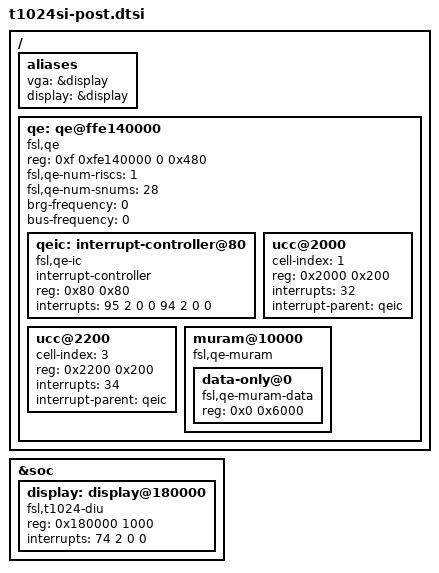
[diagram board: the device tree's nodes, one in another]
#include "t1023si-post.dtsi"
/ {
	aliases {
		vga = &display;
		display = &display;
	};
	qe:qe@ffe140000 {
		#address-cells = <1>;
		#size-cells = <1>;
		device_type = "qe";
		compatible = "fsl,qe";
		ranges = <0x0 0xf 0xfe140000 0x40000>;
		reg = <0xf 0xfe140000 0 0x480>;
		fsl,qe-num-riscs = <1>;
		fsl,qe-num-snums = <28>;
		brg-frequency = <0>;
		bus-frequency = <0>;
	};
};
&soc {
	display:display@180000 {
		compatible = "fsl,t1024-diu", "fsl,diu";
		reg = <0x180000 1000>;
		interrupts = <74 2 0 0>;
	};
};
&qe {
	qeic: interrupt-controller@80 {
		interrupt-controller;
		compatible = "fsl,qe-ic";
		#address-cells = <0>;
		#interrupt-cells = <1>;
		reg = <0x80 0x80>;
		interrupts = <95 2 0 0  94 2 0 0>;  
	};
	ucc@2000 {
		cell-index = <1>;
		reg = <0x2000 0x200>;
		interrupts = <32>;
		interrupt-parent = <&qeic>;
	};
	ucc@2200 {
		cell-index = <3>;
		reg = <0x2200 0x200>;
		interrupts = <34>;
		interrupt-parent = <&qeic>;
	};
	muram@10000 {
		#address-cells = <1>;
		#size-cells = <1>;
		compatible = "fsl,qe-muram", "fsl,cpm-muram";
		ranges = <0x0 0x10000 0x6000>;
		data-only@0 {
			compatible = "fsl,qe-muram-data", "fsl,cpm-muram-data";
			reg = <0x0 0x6000>;
		};
	};
};
